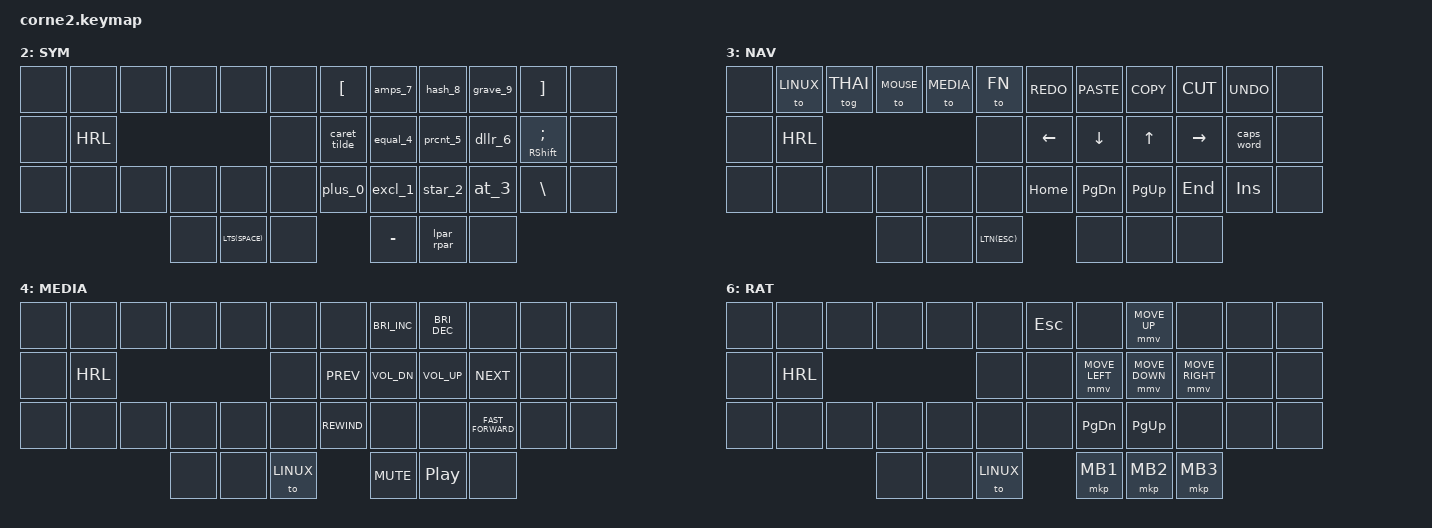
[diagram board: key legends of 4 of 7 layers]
/*
 * Copyright (c) 2020 The ZMK Contributors
 *
 * SPDX-License-Identifier: MIT
 */

#include <behaviors.dtsi>
#include <dt-bindings/zmk/keys.h>
#include <dt-bindings/zmk/bt.h>
#include <dt-bindings/zmk/outputs.h>
#include <dt-bindings/zmk/mouse.h>

// -----------------------------------------------------------------------------------------
// define layout

#define LINUX  0
#define THAI   1
#define SYM    2
#define NAV    3
#define MEDIA  4
#define FN     5
#define MOUSE  6

#define XXX &none

// -----------------------------------------------------------------------------------------
// define Layer-tap

#define LTS(k1)  &lt SYM k1
#define LTN(k1)  &lt NAV k1
#define LTM(k1)  &lt MEDIA k1
#define LTF(k1)  &lt FN k1

// -----------------------------------------------------------------------------------------
// define Home-row modifiers
#define HRML(k1,k2,k3,k4) &ht LSHIFT k1 &ht LCTRL k2 &ht LALT k3 &ht LMETA  k4
#define HRMR(k1,k2,k3,k4) &ht RMETA  k1 &ht RALT  k2 &ht RCTRL  k3 &ht RSHIFT k4
#define HRL &kp LSHIFT &kp LCTRL &kp LALT &kp LMETA
#define HRR &kp RMETA &kp RALT &kp RCTRL &kp RSHIFT

// -----------------------------------------------------------------------------------------
// define MOUSE properties

#define U_MOUSE_MOVE_MAX 1250
#define U_MOUSE_MOVE_EXPONENT 1
#define U_MOUSE_MOVE_TIME 1500
#define U_MOUSE_MOVE_DELAY 0

#undef MOVE_UP
#undef MOVE_DOWN
#undef MOVE_LEFT
#undef MOVE_RIGHT

#define MOVE_UP MOVE_VERT(-U_MOUSE_MOVE_MAX)
#define MOVE_DOWN MOVE_VERT(U_MOUSE_MOVE_MAX)
#define MOVE_LEFT MOVE_HOR(-U_MOUSE_MOVE_MAX)
#define MOVE_RIGHT MOVE_HOR(U_MOUSE_MOVE_MAX)

&mmv {
  acceleration-exponent = <U_MOUSE_MOVE_EXPONENT>;
  time-to-max-speed-ms = <U_MOUSE_MOVE_TIME>;
  delay-ms = <U_MOUSE_MOVE_DELAY>;
};

#define U_BTN1 &mkp MB1
#define U_BTN2 &mkp MB2
#define U_BTN3 &mkp MB3
#define U_MS_D &mmv MOVE_DOWN
#define U_MS_L &mmv MOVE_LEFT
#define U_MS_R &mmv MOVE_RIGHT
#define U_MS_U &mmv MOVE_UP

// -----------------------------------------------------------------------------------------
// define Hold-tap properties

#define TAPPING_TERM_MS 150
#define QUICK_TAP_MS 150

// -----------------------------------------------------------------------------------------
/ {
// -----------------------------------------------------------------------------------------
        behaviors {
// -----------------------------------------------------------------------------------------
        ht: hold_tap {
            label = "hold_tap";
            compatible = "zmk,behavior-hold-tap";
            #binding-cells = <2>;
            flavor = "tap-preferred";
            tapping-term-ms = <TAPPING_TERM_MS>;
            quick-tap-ms = <QUICK_TAP_MS>;
            global-quick-tap;
            bindings = <&kp>, <&kp>;
        };

// -----------------------------------------------------------------------------------------
        bspc_del: backspace_delete {
            compatible = "zmk,behavior-mod-morph";
            label = "BACKSPACE_DELETE";
            #binding-cells = <0>;
            bindings = <&kp BACKSPACE>, <&kp DELETE>;
            mods = <(MOD_LSFT|MOD_RSFT)>;
            keep-mods = <(MOD_RSFT)>;
        };
// -----------------------------------------------------------------------------------------
        htst: ht_space_tab {
            label = "hold_tap_space_tab";
            compatible = "zmk,behavior-hold-tap";
            #binding-cells = <2>;
            flavor = "tap-preferred";
            tapping-term-ms = <TAPPING_TERM_MS>;
            quick-tap-ms = <QUICK_TAP_MS>;
            global-quick-tap;
            bindings = <&mo>, <&space_tab>;
        };
        space_tab: space_tab {
            compatible = "zmk,behavior-mod-morph";
            label = "SPACE_TAB";
            #binding-cells = <0>;
            bindings = <&kp SPACE>, <&kp TAB>;
            mods = <(MOD_LSFT|MOD_RSFT)>;
            keep-mods = <(MOD_RSFT)>;
        };

        htest: ht_esc_stab {
            label = "hold_tap_esc_stab";
            compatible = "zmk,behavior-hold-tap";
            #binding-cells = <2>;
            flavor = "tap-preferred";
            tapping-term-ms = <TAPPING_TERM_MS>;
            quick-tap-ms = <QUICK_TAP_MS>;
            global-quick-tap;
            bindings = <&mo>, <&esc_stab>;
        };
        esc_stab: esc_stab {
            compatible = "zmk,behavior-mod-morph";
            label = "ESC_STAB";
            #binding-cells = <0>;
            bindings = <&kp ESC>, <&kp LS(TAB)>;
            mods = <(MOD_LSFT|MOD_RSFT)>;
            keep-mods = <(MOD_RSFT)>;
        };
    };
// -----------------------------------------------------------------------------------------
// MORPH NUM LAYER
        excl_1: excl_1 {
            compatible = "zmk,behavior-mod-morph";
            label = "EXCL_1";
            #binding-cells = <0>;
            bindings = <&kp EXCL>, <&kp N1>;
            mods = <(MOD_LSFT|MOD_RSFT)>;
            keep-mods = <(MOD_RSFT)>;
        };
        star_2: star_2 {
            compatible = "zmk,behavior-mod-morph";
            label = "STAR_1";
            #binding-cells = <0>;
            bindings = <&kp STAR>, <&kp N2>;
            mods = <(MOD_LSFT|MOD_RSFT)>;
            keep-mods = <(MOD_RSFT)>;
        };
        at_3: at_3 {
            compatible = "zmk,behavior-mod-morph";
            label = "AT_3";
            #binding-cells = <0>;
            bindings = <&kp AT>, <&kp N3>;
            mods = <(MOD_LSFT|MOD_RSFT)>;
            keep-mods = <(MOD_RSFT)>;
        };
        equal_4: equal_4 {
            compatible = "zmk,behavior-mod-morph";
            label = "EQUAL_4";
            #binding-cells = <0>;
            bindings = <&kp EQUAL>, <&kp N4>;
            mods = <(MOD_LSFT|MOD_RSFT)>;
            keep-mods = <(MOD_RSFT)>;
        };
        prcnt_5: prcnt_5 {
            compatible = "zmk,behavior-mod-morph";
            label = "PRCNT_5";
            #binding-cells = <0>;
            bindings = <&kp PRCNT>, <&kp N5>;
            mods = <(MOD_LSFT|MOD_RSFT)>;
            keep-mods = <(MOD_RSFT)>;
        };
        dllr_6: dllr_6 {
            compatible = "zmk,behavior-mod-morph";
            label = "DLLR_6";
            #binding-cells = <0>;
            bindings = <&kp DLLR>, <&kp N6>;
            mods = <(MOD_LSFT|MOD_RSFT)>;
            keep-mods = <(MOD_RSFT)>;
        };
        amps_7: amps_7 {
            compatible = "zmk,behavior-mod-morph";
            label = "AMPS_7";
            #binding-cells = <0>;
            bindings = <&kp AMPS>, <&kp N7>;
            mods = <(MOD_LSFT|MOD_RSFT)>;
            keep-mods = <(MOD_RSFT)>;
        };
        hash_8: hash_8 {
            compatible = "zmk,behavior-mod-morph";
            label = "HASH_8";
            #binding-cells = <0>;
            bindings = <&kp HASH>, <&kp N8>;
            mods = <(MOD_LSFT|MOD_RSFT)>;
            keep-mods = <(MOD_RSFT)>;
        };
        grave_9: grave_9 {
            compatible = "zmk,behavior-mod-morph";
            label = "GRAVE_9";
            #binding-cells = <0>;
            bindings = <&kp GRAVE>, <&kp N9>;
            mods = <(MOD_LSFT|MOD_RSFT)>;
            keep-mods = <(MOD_RSFT)>;
        };
        lpar_rpar: lpar_rpar {
            compatible = "zmk,behavior-mod-morph";
            label = "LPAR_RPAR";
            #binding-cells = <0>;
            bindings = <&kp LPAR>, <&kp RPAR>;
            mods = <(MOD_LSFT|MOD_RSFT)>;
            keep-mods = <(MOD_RSFT)>;
        };
        plus_0: plus_0 {
            compatible = "zmk,behavior-mod-morph";
            label = "PLUS_0";
            #binding-cells = <0>;
            bindings = <&kp PLUS>, <&kp N0>;
            mods = <(MOD_LSFT|MOD_RSFT)>;
            keep-mods = <(MOD_RSFT)>;
        };
        caret_tilde: caret_tilde {
            compatible = "zmk,behavior-mod-morph";
            label = "CARET_TILDE";
            #binding-cells = <0>;
            bindings = <&kp CARET>, <&kp TILDE>;
            mods = <(MOD_LSFT|MOD_RSFT)>;
            keep-mods = <(MOD_RSFT)>;
        };

// -----------------------------------------------------------------------------------------
// MORPH THAI LAYER

//      SHIFT HOLD TAP MORPH

        httl: ht_thai_left {
            label = "hold_tap_thai_left";
            compatible = "zmk,behavior-hold-tap";
            #binding-cells = <2>;
            flavor = "tap-preferred";
            tapping-term-ms = <TAPPING_TERM_MS>;
            quick-tap-ms = <QUICK_TAP_MS>;
            global-quick-tap;
            bindings = <&kp>, <&apos_k>;
        };
        httr: ht_thai_right {
            label = "hold_tap_thai_right";
            compatible = "zmk,behavior-hold-tap";
            #binding-cells = <2>;
            flavor = "tap-preferred";
            tapping-term-ms = <TAPPING_TERM_MS>;
            quick-tap-ms = <QUICK_TAP_MS>;
            global-quick-tap;
            bindings = <&kp>, <&semi_4>;
        };

//      MORPH
        
        dot_lt: dot_lt {
            compatible = "zmk,behavior-mod-morph";
            label = "DOT_LT";
            #binding-cells = <0>;
            bindings = <&kp DOT>, <&kp LT>;
            mods = <(MOD_LSFT|MOD_RSFT)>;
        };
        nine_d: nine_d {
            compatible = "zmk,behavior-mod-morph";
            label = "NINE_D";
            #binding-cells = <0>;
            bindings = <&kp N9>, <&kp LS(D)>;
            mods = <(MOD_LSFT|MOD_RSFT)>;
        };
        s_colon: s_colon {
            compatible = "zmk,behavior-mod-morph";
            label = "S_COLON";
            #binding-cells = <0>;
            bindings = <&kp S>, <&kp COLON>;
            mods = <(MOD_LSFT|MOD_RSFT)>;
        };
        rbkt_p: rbkt_p {
            compatible = "zmk,behavior-mod-morph";
            label = "RBKT_P";
            #binding-cells = <0>;
            bindings = <&kp RBKT>, <&kp LS(P)>;
            mods = <(MOD_LSFT|MOD_RSFT)>;
        };
        l_a: l_a {
            compatible = "zmk,behavior-mod-morph";
            label = "L_A";
            #binding-cells = <0>;
            bindings = <&kp L>, <&kp A>;
            mods = <(MOD_LSFT|MOD_RSFT)>;
        };
        x_c: x_c {
            compatible = "zmk,behavior-mod-morph";
            label = "X_C";
            #binding-cells = <0>;
            bindings = <&kp X>, <&kp LS(C)>;
            mods = <(MOD_LSFT|MOD_RSFT)>;
        };
        y_7: y_7 {
            compatible = "zmk,behavior-mod-morph";
            label = "Y_7";
            #binding-cells = <0>;
            bindings = <&kp Y>, <&kp N7>;
            mods = <(MOD_LSFT|MOD_RSFT)>;
        };
        d_t: d_t {
            compatible = "zmk,behavior-mod-morph";
            label = "D_T";
            #binding-cells = <0>;
            bindings = <&kp D>, <&kp LS(T)>;
            mods = <(MOD_LSFT|MOD_RSFT)>;
        };
        b_lbrc: b_lbrc {
            compatible = "zmk,behavior-mod-morph";
            label = "B_LBRC";
            #binding-cells = <0>;
            bindings = <&kp B>, <&kp LBRC>;
            mods = <(MOD_LSFT|MOD_RSFT)>;
        };
        lbkt_h: lbkt_h {
            compatible = "zmk,behavior-mod-morph";
            label = "LBKT_H";
            #binding-cells = <0>;
            bindings = <&kp LBKT>, <&kp LS(H)>;
            mods = <(MOD_LSFT|MOD_RSFT)>;
        };
        apos_k: apos_k {
            compatible = "zmk,behavior-mod-morph";
            label = "APOS_K";
            #binding-cells = <0>;
            bindings = <&kp APOS>, <&kp LS(K)>;
            mods = <(MOD_LSFT|MOD_RSFT)>;
        };
        g_5: g_5 {
            compatible = "zmk,behavior-mod-morph";
            label = "G_5";
            #binding-cells = <0>;
            bindings = <&kp G>, <&kp N5>;
            mods = <(MOD_LSFT|MOD_RSFT)>;
        };
        i_c: i_c {
            compatible = "zmk,behavior-mod-morph";
            label = "I_C";
            #binding-cells = <0>;
            bindings = <&kp I>, <&kp C>;
            mods = <(MOD_LSFT|MOD_RSFT)>;
        };
        o_equal: o_equal {
            compatible = "zmk,behavior-mod-morph";
            label = "O_EQUAL";
            #binding-cells = <0>;
            bindings = <&kp O>, <&kp EQUAL>;
            mods = <(MOD_LSFT|MOD_RSFT)>;
        };
        comma_r: comma_r {
            compatible = "zmk,behavior-mod-morph";
            label = "COMMA_R";
            #binding-cells = <0>;
            bindings = <&kp COMMA>, <&kp LS(R)>;
            mods = <(MOD_LSFT|MOD_RSFT)>;
        };
        v_z: v_z {
            compatible = "zmk,behavior-mod-morph";
            label = "V_Z";
            #binding-cells = <0>;
            bindings = <&kp V>, <&kp Z>;
            mods = <(MOD_LSFT|MOD_RSFT)>;
        };
        k_e: k_e {
            compatible = "zmk,behavior-mod-morph";
            label = "K_E";
            #binding-cells = <0>;
            bindings = <&kp K>, <&kp E>;
            mods = <(MOD_LSFT|MOD_RSFT)>;
        };
        j_minus: j_minus {
            compatible = "zmk,behavior-mod-morph";
            label = "J_MINUS";
            #binding-cells = <0>;
            bindings = <&kp J>, <&kp MINUS>;
            mods = <(MOD_LSFT|MOD_RSFT)>;
        };
        h_f: h_f {
            compatible = "zmk,behavior-mod-morph";
            label = "H_F";
            #binding-cells = <0>;
            bindings = <&kp H>, <&kp LS(F)>;
            mods = <(MOD_LSFT|MOD_RSFT)>;
        };
        semi_4: semi_4 {
            compatible = "zmk,behavior-mod-morph";
            label = "SEMI_4";
            #binding-cells = <0>;
            bindings = <&kp SEMI>, <&kp N4>;
            mods = <(MOD_LSFT|MOD_RSFT)>;
        };
        six_a: six_a {
            compatible = "zmk,behavior-mod-morph";
            label = "SIX_A";
            #binding-cells = <0>;
            bindings = <&kp N6>, <&kp LS(A)>;
            mods = <(MOD_LSFT|MOD_RSFT)>;
        };
        w_slash: w_slash {
            compatible = "zmk,behavior-mod-morph";
            label = "W_SLASH";
            #binding-cells = <0>;
            bindings = <&kp W>, <&kp SLASH>;
            mods = <(MOD_LSFT|MOD_RSFT)>;
        };
        m_q: m_q {
            compatible = "zmk,behavior-mod-morph";
            label = "M_Q";
            #binding-cells = <0>;
            bindings = <&kp M>, <&kp Q>;
            mods = <(MOD_LSFT|MOD_RSFT)>;
        };
        p_i: p_i {
            compatible = "zmk,behavior-mod-morph";
            label = "P_I";
            #binding-cells = <0>;
            bindings = <&kp P>, <&kp I>;
            mods = <(MOD_LSFT|MOD_RSFT)>;
        };
        zero_u: zero_u {
            compatible = "zmk,behavior-mod-morph";
            label = "ZERO_U";
            #binding-cells = <0>;
            bindings = <&kp N0>, <&kp LS(U)>;
            mods = <(MOD_LSFT|MOD_RSFT)>;
        };
        eight_j: eight_j {
            compatible = "zmk,behavior-mod-morph";
            label = "EIGHT_J";
            #binding-cells = <0>;
            bindings = <&kp N8>, <&kp LS(J)>;
            mods = <(MOD_LSFT|MOD_RSFT)>;
        };
        u_n: u_n {
            compatible = "zmk,behavior-mod-morph";
            label = "U_N";
            #binding-cells = <0>;
            bindings = <&kp U>, <&kp LS(N)>;
            mods = <(MOD_LSFT|MOD_RSFT)>;
        };
        f_l: f_l {
            compatible = "zmk,behavior-mod-morph";
            label = "F_L";
            #binding-cells = <0>;
            bindings = <&kp F>, <&kp LS(L)>;
            mods = <(MOD_LSFT|MOD_RSFT)>;
        };
        t_v: t_v {
            compatible = "zmk,behavior-mod-morph";
            label = "T_V";
            #binding-cells = <0>;
            bindings = <&kp T>, <&kp LS(V)>;
            mods = <(MOD_LSFT|MOD_RSFT)>;
        };
        caret_n: caret_n {
            compatible = "zmk,behavior-mod-morph";
            label = "CARET_N";
            #binding-cells = <0>;
            bindings = <&kp CARET>, <&kp N>;
            mods = <(MOD_LSFT|MOD_RSFT)>;
        };

// -----------------------------------------------------------------------------------------
        macros {
// -----------------------------------------------------------------------------------------
        thumb_tap: thumb_tap {
            label = "thumb_tap";
            compatible = "zmk,behavior-macro";
            #binding-cells = <0>;
            bindings
                = <&macro_press &kp TAB>
                , <&macro_tap &kp Z &kp M &kp K>
                , <&macro_release &kp TAB>
                ;
        };
    };

// -----------------------------------------------------------------------------------------
        combos {
// -----------------------------------------------------------------------------------------
        compatible = "zmk,combos";
        combo_jk_esc {
            timeout-ms = <50>;
            key-positions = <19 20>;
            bindings = <&kp ESC>;
        };
    };

// -----------------------------------------------------------------------------------------
        keymap {
                compatible = "zmk,keymap";

// -----------------------------------------------------------------------------------------
                linux_layer {
// -----------------------------------------------------------------------------------------
                        label = "LINUX";
                        bindings = <
//      ╭──────────┬──────────┬──────────┬──────────┬──────────╮   ╭──────────┬──────────┬──────────┬──────────┬──────────╮
//      │  Q       │  W       │  E       │  R       │  T       │   │  Y       │  U       │  I       │  O       │  P       │
   XXX    &kp Q      &kp W      &kp E      &kp R      &kp T          &kp Y      &kp U      &kp I      &kp O      &kp P       XXX
//      ├──────────┼──────────┼──────────┼──────────┼──────────┤   ├──────────┼──────────┼──────────┼──────────┼──────────┤
//      │  A       │  S       │  D       │  F       │  G       │   │  H       │  J       │  K       │  L       │  ' "     │
   XXX   HRML(A,      S,         D,         F)         &kp G         &kp H      HRMR(J,     K,         L,         APOS)      XXX
//      ├──────────┼──────────┼──────────┼──────────┼──────────┤   ├──────────┼──────────┼──────────┼──────────┼──────────┤
//      │  Z       │  X       │  C       │  V       │  B       │   │  N       │  M       │  , <     │  . >     │  / ?     │
   XXX    &kp Z      &kp X      &kp C      &kp V      &kp B          &kp N      &kp M      &kp COMMA  &kp DOT    &kp FSLH    XXX
//      ╰──────────┴──────────┴──────────┴──────────┴──────────╯   ╰──────────┴──────────┴──────────┴──────────┴──────────╯
//                    ╭─────────────┬─────────────┬────────────╮   ╭────────────┬──────────────┬─────────────╮
//                    │     X       │SPACE/SYM/TAB│ESC/NAV/STAB│   │    RET     │    BSPC      │      X      │
                           XXX        &htst SYM 0  &htest NAV 0       &kp RET      &bspc_del         XXX
//                    ╰─────────────┴─────────────┴────────────╯   ╰────────────┴──────────────┴─────────────╯
                        >;
                };

// -----------------------------------------------------------------------------------------
                thai_layer {
// -----------------------------------------------------------------------------------------
                        label = "THAI";
                        bindings = <
//      ╭──────────┬──────────┬──────────┬──────────┬──────────╮   ╭──────────┬──────────┬──────────┬──────────┬──────────╮
   XXX    &dot_lt    &nine_d    &s_colon   &rbkt_p      &l_a          &x_c        &y_7      &d_t       &b_lbrc    &lbkt_h      XXX
//      ├──────────┼──────────┼──────────┼──────────┼──────────┤   ├──────────┼──────────┼──────────┼──────────┼──────────┤
//      │   ' K    │    g 5   │    i c   │    o =   │   , r    │   │   v z    │    k e   │   j -    │  h F     │    ; 4   │
   XXX  &httl LSHIFT 0 &g_5       &i_c     &o_equal    &comma_r        &v_z       &k_e      &j_minus  &h_f     &httr RSHIFT 0  XXX
//      ├──────────┼──────────┼──────────┼──────────┼──────────┤   ├──────────┼──────────┼──────────┼──────────┼──────────┤
//      │  6 A     │    w /   │    m q   │    p I   │    0 U   │   │     8 J  │    u N   │    f L   │    t V   │    ^ n 
   XXX    &six_a       &w_slash    &m_q       &p_i     &zero_u       &eight_j     &u_n        &f_l       &t_v     &caret_n     XXX
//      ╰──────────┴──────────┴──────────┴──────────┴──────────╯   ╰──────────┴──────────┴──────────┴──────────┴──────────╯
//                    ╭─────────────┬─────────────┬────────────╮   ╭────────────┬──────────────┬─────────────╮
//                    │    X        │SPACE/SYM/TAB│ESC/NAV/STAB│   │    RET     │    BSPC      │      X      │
                          XXX         &htst SYM 0  &htest NAV 0       &kp RET      &bspc_del         XXX
//                    ╰─────────────┴─────────────┴────────────╯   ╰────────────┴──────────────┴─────────────╯
                        >;
                };

// -----------------------------------------------------------------------------------------
                sym_layer {
// -----------------------------------------------------------------------------------------
                        label = "SYM";
                        bindings = <
//      ╭──────────┬──────────┬──────────┬──────────┬──────────╮   ╭──────────┬──────────┬──────────┬──────────┬──────────╮
//      │  X       │  X       │  X       │  X       │  X       │   │   [ {    │   & 7    │   # 8    │   ` 9    │   ] }    │
   XXX    XXX         XXX        XXX        XXX        XXX          &kp LBKT    &amps_7     &hash_8   &grave_9   &kp RBKT         XXX
//      ├──────────┼──────────┼──────────┼──────────┼──────────┤   ├──────────┼──────────┼──────────┼──────────┼──────────┤
//      │  LSHIFT  │  LCTRL   │  LALT    │  LMETA   │  X       │   │   ^ ~    │   = 4    │   % 5    │   6 $    │  ; :     │
   XXX      HRL                                        XXX         &caret_tilde  &equal_4   &prcnt_5   &dllr_6  &ht RSHIFT SEMI   XXX 
//      ├──────────┼──────────┼──────────┼──────────┼──────────┤   ├──────────┼──────────┼──────────┼──────────┼──────────┤
//      │  X       │  X       │  X       │  X       │  X       │   │    + 0   │   ! 1    │   * 2    │   @ 3    │   \ |    │
   XXX    XXX         XXX        XXX        XXX        XXX            &plus_0    &excl_1   &star_2     &at_3     &kp BSLH         XXX
//      ╰──────────┴──────────┴──────────┴──────────┴──────────╯   ╰──────────┴──────────┴──────────┴──────────┴──────────╯
//                    ╭─────────────┬─────────────┬────────────╮   ╭────────────┬──────────────┬─────────────╮
//                    │      X      │  SPACE/SYM  │     X      │   │    - _     │    ( )       │    X        │
                            XXX        LTS(SPACE)      XXX            &kp MINUS     &lpar_rpar     XXX
//                    ╰─────────────┴─────────────┴────────────╯   ╰────────────┴──────────────┴─────────────╯
                        >;
                };

// -----------------------------------------------------------------------------------------
                nav_layer {
// -----------------------------------------------------------------------------------------
                        label = "NAV";
                        bindings = <
//      ╭──────────┬──────────┬──────────┬──────────┬──────────╮   ╭──────────┬──────────┬──────────┬──────────┬──────────╮
//      │  BASE    │   THAI   │  MOUSE   │  MEDIA   │  FN      │   │  REDO    │  PASTE   │  COPY    │  CUT     │  UNDO    │
   XXX    &to LINUX  &tog THAI  &to MOUSE  &to MEDIA  &to FN        &kp K_REDO &kp K_PASTE &kp K_COPY &kp K_CUT &kp K_UNDO   XXX
//      ├──────────┼──────────┼──────────┼──────────┼──────────┤   ├──────────┼──────────┼──────────┼──────────┼──────────┤
//      │  LSHIFT  │  LCTRL   │  LALT    │  LMETA   │    X     │   │  LEFT    │  DOWN    │    UP    │  RIGHT   │  CAPS    │
   XXX      HRL                                         XXX          &kp LEFT    &kp DOWN    &kp UP    &kp RIGHT &caps_word  XXX 
//      ├──────────┼──────────┼──────────┼──────────┼──────────┤   ├──────────┼──────────┼──────────┼──────────┼──────────┤
//      │  X       │  X       │  X       │  X       │    X     │   │  HOME    │  PG_DN   │  PG_UP   │  END     │  INS     │
   XXX    XXX         XXX        XXX        XXX          XXX         &kp HOME   &kp PG_DN  &kp PG_UP   &kp END    &kp INS    XXX
//      ╰──────────┴──────────┴──────────┴──────────┴──────────╯   ╰──────────┴──────────┴──────────┴──────────┴──────────╯
//                    ╭─────────────┬─────────────┬────────────╮   ╭────────────┬──────────────┬─────────────╮
//                    │      X      │      X      │   ESC/NAV  │   │     X      │       X      │     X       │
                            XXX           XXX         LTN(ESC)          XXX           XXX           XXX
//                    ╰─────────────┴─────────────┴────────────╯   ╰────────────┴──────────────┴─────────────╯
                        >;
                };


// -----------------------------------------------------------------------------------------
                media_layer {
// -----------------------------------------------------------------------------------------
                        label = "MEDIA";
                        bindings = <
//      ╭──────────┬──────────┬──────────┬──────────┬──────────╮   ╭─────────────────┬──────────────────────┬─────────────────────┬────────────────┬────────────────╮
//      │  X       │  X       │  X       │  X       │  X       │   │       X         │          BRI_UP      │        BRI_DN       │       X        │      X         │
   XXX    XXX         XXX        XXX        XXX        XXX                XXX          &kp C_BRIGHTNESS_INC   &kp C_BRIGHTNESS_DEC       XXX             XXX           XXX
//      ├──────────┼──────────┼──────────┼──────────┼──────────┤   ├─────────────────┼──────────────────────┼─────────────────────┼────────────────┼────────────────┤
//      │  X       │  X       │  X       │  X       │  X       │   │      Prev       │       Vol down       │        Vol up       │      Next      │      X         │
   XXX    HRL                                          XXX              &kp C_PREV         &kp C_VOL_DN           &kp C_VOL_UP        &kp C_NEXT         XXX           XXX 
//      ├──────────┼──────────┼──────────┼──────────┼──────────┤   ├─────────────────┼──────────────────────┼─────────────────────┼────────────────┼────────────────┤
//      │  X       │  X       │  X       │  X       │  X       │   │     REWIND      │           X          │           X         │      FFWD      │      X         │
   XXX    XXX         XXX        XXX        XXX        XXX             &kp C_REWIND             XXX                    XXX         &kp C_FAST_FORWARD    XXX           XXX
//      ╰──────────┴──────────┴──────────┴──────────┴──────────╯   ╰─────────────────┴──────────────────────┴─────────────────────┴────────────────┴────────────────╯
//                    ╭─────────────┬─────────────┬────────────╮   ╭────────────┬──────────────┬─────────────╮
//                    │    X        │      X      │  TO BASE   │   │  Mute      │  Play/Pause  │    X        │
                          XXX             XXX        &to LINUX       &kp C_MUTE     &kp C_PP       XXX
//                    ╰─────────────┴─────────────┴────────────╯   ╰────────────┴──────────────┴─────────────╯
                        >;
                };

// -----------------------------------------------------------------------------------------
                fn_layer {
// -----------------------------------------------------------------------------------------
                        label = "FN";
                        bindings = <
//      ╭──────────┬──────────┬──────────┬──────────┬──────────╮   ╭──────────────┬─────────────┬──────────────┬──────────────┬──────────────╮
//      │   F12    │    F7    │    F8    │    F9    │  PSCRN   │   │    BT_PRV    │   BT_PRV    │    BT_NXT    │   BT_NXT     │   BT_CLR     │
   XXX    &kp F12    &kp F7     &kp F8     &kp F9    &kp PSCRN        &bt BT_PRV    &bt BT_PRV     &bt BT_NXT     &bt BT_NXT     &bt BT_CLR     XXX
//      ├──────────┼──────────┼──────────┼──────────┼──────────┤   ├──────────────┼─────────────┼──────────────┼──────────────┼──────────────┤
//      │   F11    │    F4    │    F5    │    F6    │  NUMLOCK │   │   BEHAVIOR   │    RMETA    │    RALT      │     RCTRL    │   RSHIFT     │
   XXX    &kp F11    &kp F4     &kp F5     &kp F6   &kp KP_NLCK      &out OUT_TOG    &kp RMETA      &kp RALT      &kp RCTRL     &kp RSHIFT      XXX
//      ├──────────┼──────────┼──────────┼──────────┼──────────┤   ├──────────────┼─────────────┼──────────────┼──────────────┼──────────────┤
//      │   F10    │    F1    │    F2    │    F3    │  BREAK   │   │   BT_SEL 1   │  BT_SEL 2   │   BT_SEL 3   │   BT_SEL 4   │   BT_SEL 5   │
   XXX    &kp F10    &kp F1     &kp F2     &kp F3  &kp PAUSE_BREAK   &bt BT_SEL 1   &bt BT_SEL 2   &bt BT_SEL 3  &bt BT_SEL 4    &bt BT_SEL 5   XXX
//      ╰──────────┴──────────┴──────────┴──────────┴──────────╯   ╰──────────────┴─────────────┴──────────────┴──────────────┴──────────────╯
//                    ╭─────────────┬─────────────┬────────────╮   ╭────────────┬──────────────┬─────────────╮
//                    │      X      │      X      │   TO BASE  │   │     X      │      X       │      X      │
                            XXX           XXX        &to LINUX          XXX           XXX            XXX
//                    ╰─────────────┴─────────────┴────────────╯   ╰────────────┴──────────────┴─────────────╯
                        >;
                };

// -----------------------------------------------------------------------------------------
                mouse_layer {
// -----------------------------------------------------------------------------------------
                        label = "RAT";
                        bindings = <
//      ╭──────────┬──────────┬──────────┬──────────┬──────────╮   ╭──────────┬──────────┬──────────┬──────────┬──────────╮
//      │   X      │   X      │   X      │   X      │   X      │   │   ESC    │   X      │  MOVE_UP │   X      │   X      │
   XXX     XXX        XXX        XXX        XXX        XXX            &kp ESC     XXX       U_MS_U      XXX        XXX       XXX
//      ├──────────┼──────────┼──────────┼──────────┼──────────┤   ├──────────┼──────────┼──────────┼──────────┼──────────┤
//      │   X      │   X      │   X      │   X      │   X      │   │   X      │ MOVE_LEFT│ MOVE_DOWN│MOVE_RIGHT│   X      │
   XXX     HRL                                         XXX            XXX        U_MS_L    U_MS_D     U_MS_R       XXX       XXX
//      ├──────────┼──────────┼──────────┼──────────┼──────────┤   ├──────────┼──────────┼──────────┼──────────┼──────────┤
//      │   X      │   X      │   X      │   X      │   X      │   │   X      │  PG_DN   │  PG_UP   │   X      │   X      │
   XXX     XXX        XXX        XXX        XXX        XXX             XXX      &kp PG_DN  &kp PG_UP    XXX        XXX       XXX
//      ╰──────────┴──────────┴──────────┴──────────┴──────────╯   ╰──────────┴──────────┴──────────┴──────────┴──────────╯
//                    ╭─────────────┬─────────────┬────────────╮   ╭────────────┬──────────────┬─────────────╮
//                    │      X      │      X      │   TO BASE  │   │   LCLICK   │    RCLICK    │    MCLICK   │
                            XXX           XXX        &to LINUX         U_BTN1        U_BTN2         U_BTN3 
//                    ╰─────────────┴─────────────┴────────────╯   ╰────────────┴──────────────┴─────────────╯
                        >;
                };

// -----------------------------------------------------------------------------------------
        };
};
